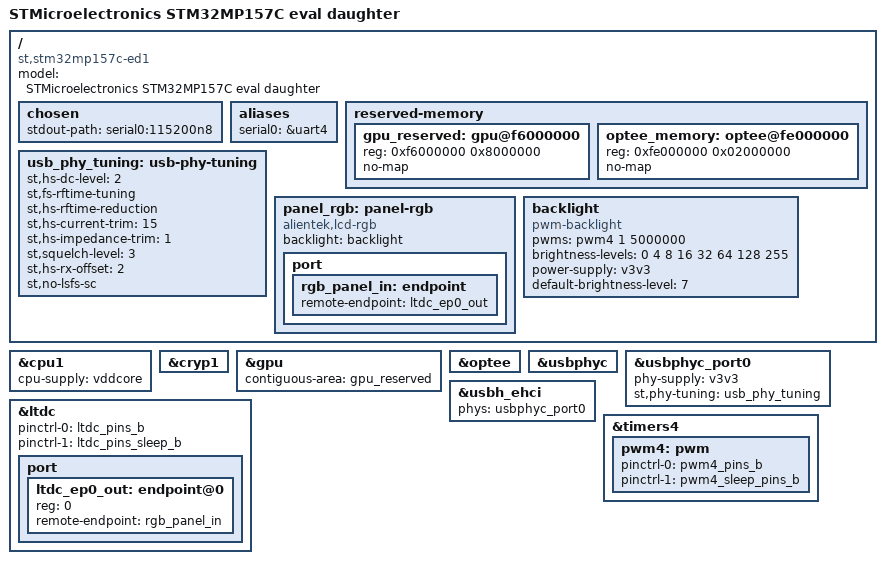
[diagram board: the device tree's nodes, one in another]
// SPDX-License-Identifier: (GPL-2.0+ OR BSD-3-Clause)
/*
 * Copyright (C) STMicroelectronics 2019 - All Rights Reserved
 * Author: Alexandre Torgue <alexandre.torgue@st.com> for STMicroelectronics.
 */
/dts-v1/;

#include "stm32mp157.dtsi"
#include "stm32mp15xc.dtsi"
#include "stm32mp15-pinctrl.dtsi"
#include "stm32mp15xxaa-pinctrl.dtsi"
#include "stm32mp157-m4-srm.dtsi"
#include "stm32mp157-m4-srm-pinctrl.dtsi"
#include "stm32mp157d-atk.dtsi"

/ {
	model = "STMicroelectronics STM32MP157C eval daughter";
	compatible = "st,stm32mp157c-ed1", "st,stm32mp157";

	chosen {
		stdout-path = "serial0:115200n8";
	};

	aliases {
		serial0 = &uart4;
	};

	reserved-memory {
		gpu_reserved: gpu@f6000000 {
			reg = <0xf6000000 0x8000000>;
			no-map;
		};

		optee_memory: optee@fe000000 {
			reg = <0xfe000000 0x02000000>;
			no-map;
		};
	};

	usb_phy_tuning: usb-phy-tuning {
		st,hs-dc-level = <2>;
		st,fs-rftime-tuning;
		st,hs-rftime-reduction;
		st,hs-current-trim = <15>;
		st,hs-impedance-trim = <1>;
		st,squelch-level = <3>;
		st,hs-rx-offset = <2>;
		st,no-lsfs-sc;
	};

	panel_rgb: panel-rgb {
		compatible = "alientek,lcd-rgb";
		backlight = <&backlight>;
		status = "okay";

		port {
			rgb_panel_in: endpoint {
				remote-endpoint = <&ltdc_ep0_out>;
			};
		};
	};

	backlight: backlight {
		compatible = "pwm-backlight";
		pwms = <&pwm4 1 5000000>;
		brightness-levels = <0 4 8 16 32 64 128 255>;
		power-supply = <&v3v3>;
		default-brightness-level = <7>;
		status = "okay";
	};
};

&cpu1{
	cpu-supply = <&vddcore>;
};

&cryp1 {
	status="okay";
};

&gpu {
	contiguous-area = <&gpu_reserved>;
	status = "okay";
};

&optee {
	status = "okay";
};

&usbphyc {
	status = "okay";
};

&usbphyc_port0 {
	phy-supply = <&v3v3>;
	st,phy-tuning = <&usb_phy_tuning>;
};

&usbh_ehci {
	phys = <&usbphyc_port0>;
	status = "okay";
};

&ltdc {
	pinctrl-names = "default", "sleep";
	pinctrl-0 = <&ltdc_pins_b>;
	pinctrl-1 = <&ltdc_pins_sleep_b>;
	status = "okay";

	port {
		#address-cells = <1>;
		#size-cells = <0>;

		ltdc_ep0_out: endpoint@0 {
			reg = <0>;
			remote-endpoint = <&rgb_panel_in>;
		};
	};
};

&timers4 {
	status = "okay";
	/* spare dmas for other usage */
	/delete-property/dmas;
	/delete-property/dma-names;
	pwm4: pwm {
		pinctrl-0 = <&pwm4_pins_b>;
		pinctrl-1 = <&pwm4_sleep_pins_b>;
		pinctrl-names = "default", "sleep";
		#pwm-cells = <2>;
		status = "okay";
	};
};
